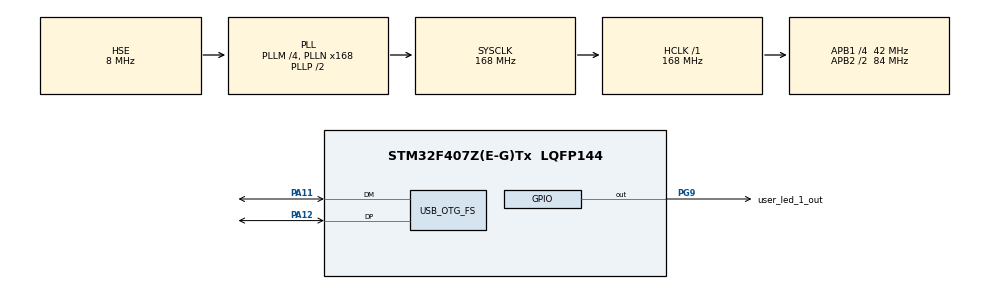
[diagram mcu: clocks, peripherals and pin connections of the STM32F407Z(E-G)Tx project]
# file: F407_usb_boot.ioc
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FATFS._MAX_SS=4096
FATFS._USE_LFN=1
Mcu.Family=STM32F4
Mcu.Name=STM32F407Z(E-G)Tx
Mcu.Package=LQFP144
NVIC.OTG_FS_IRQn=true\:0\:0\:false\:false\:true\:false\:true\:true
NVIC.PriorityGroup=NVIC_PRIORITYGROUP_4
PA11.Mode=Host_Only
PA11.Signal=USB_OTG_FS_DM
PA12.Mode=Host_Only
PA12.Signal=USB_OTG_FS_DP
PG9.GPIO_Label=user_led_1_out
PG9.Signal=GPIO_Output
PH0-OSC_IN.Mode=HSE-External-Oscillator
PH0-OSC_IN.Signal=RCC_OSC_IN
PH1-OSC_OUT.Mode=HSE-External-Oscillator
PH1-OSC_OUT.Signal=RCC_OSC_OUT
ProjectManager.HeapSize=0x200
ProjectManager.StackSize=0x400
ProjectManager.TargetToolchain=STM32CubeIDE
RCC.48MHZClocksFreq_Value=48000000
RCC.AHBFreq_Value=168000000
RCC.APB1CLKDivider=RCC_HCLK_DIV4
RCC.APB1Freq_Value=42000000
RCC.APB1TimFreq_Value=84000000
RCC.APB2CLKDivider=RCC_HCLK_DIV2
RCC.APB2Freq_Value=84000000
RCC.APB2TimFreq_Value=168000000
RCC.CortexFreq_Value=168000000
RCC.HCLKFreq_Value=168000000
RCC.HSE_VALUE=8000000
RCC.HSI_VALUE=16000000
RCC.LSE_VALUE=32768
RCC.PLLM=4
RCC.PLLN=168
RCC.PLLQ=7
RCC.SYSCLKFreq_VALUE=168000000
RCC.SYSCLKSource=RCC_SYSCLKSOURCE_PLLCLK
RCC.VCOOutputFreq_Value=336000000
USB_HOST.USBH_HandleTypeDef-MSC_FS=hUsbHostFS
USB_HOST.VirtualModeFS=Msc
USB_OTG_FS.VirtualMode=Host_Only
USB_OTG_FS.phy_itface=HCD_PHY_EMBEDDED
VP_FATFS_VS_USB.Mode=USB
VP_USB_HOST_VS_USB_HOST_MSC_FS.Mode=MSC_FS
board=custom

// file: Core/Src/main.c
/* USER CODE BEGIN Header */
/**
 ******************************************************************************
 * @file           : main.c
 * @brief          : Main program body
 ******************************************************************************
 * @attention
 *
 * Copyright (c) 2024 STMicroelectronics.
 * All rights reserved.
 *
 * This software is licensed under terms that can be found in the LICENSE file
 * in the root directory of this software component.
 * If no LICENSE file comes with this software, it is provided AS-IS.
 *
 ******************************************************************************
 */
/* USER CODE END Header */
#include "main.h"
#include "fatfs.h"
#include "usb_host.h"
#include "gpio.h"

/* USER CODE BEGIN PD */
#define application_address 	0x08040000
#define bufferSize 				512
#define file_name				"0:/F407_usb_app.bin"
#define usb_mount 				f_mount(&fatfs, USBHPath, 0)
#define usb_unmount 			f_mount(NULL, USBHPath, 0)
/* USER CODE END PD */

/* USER CODE BEGIN PV */
extern ApplicationTypeDef Appli_state;

uint32_t start = 0, end = 0;

FATFS fatfs;
FIL fil;
FRESULT fresult;
FILINFO info;

UINT bytesRead = 0;
uint8_t readBuffer[bufferSize];
/* USER CODE END PV */

void SystemClock_Config(void);
void MX_USB_HOST_Process(void);

/* USER CODE BEGIN PFP */
static void gotoApp(void);
/* USER CODE END PFP */

/* USER CODE BEGIN 0 */
void flashErase(void) {
	HAL_StatusTypeDef res;
	uint32_t sectorError;

	HAL_FLASH_Unlock();
	/* Check if the FLASH_FLAG_BSY */
	FLASH_WaitForLastOperation(HAL_MAX_DELAY);

	/* Clear all flags before write it to flash */
	__HAL_FLASH_CLEAR_FLAG(
			FLASH_FLAG_EOP | FLASH_FLAG_OPERR | FLASH_FLAG_WRPERR | FLASH_FLAG_PGAERR | FLASH_FLAG_PGPERR | FLASH_FLAG_PGSERR);

	/* Erase the flash */
	FLASH_EraseInitTypeDef flashErase;

	flashErase.TypeErase = FLASH_TYPEERASE_SECTORS;
	flashErase.Sector = FLASH_SECTOR_5;
	flashErase.NbSectors = 2;
	flashErase.VoltageRange = FLASH_VOLTAGE_RANGE_3;

	res = HAL_FLASHEx_Erase(&flashErase, &sectorError);
	if (res != HAL_OK) {
	}
}

void flashProgram(void) {
	uint32_t programBytesToRead = info.fsize;  // Get file size
	uint32_t currentAddress = application_address;

	while (programBytesToRead > 0) {
		// Read up to 512 bytes from the file
		if ((fresult = f_read(&fil, readBuffer, bufferSize, &bytesRead))
				!= FR_OK) {
		}

		// Write the data into flash memory, 4 bytes at a time
		for (uint32_t i = 0; i < bytesRead; i += 4) {
			HAL_FLASH_Program(FLASH_TYPEPROGRAM_WORD, currentAddress,
					*(uint32_t*) &readBuffer[i]);
			currentAddress += 4;
		}

		programBytesToRead -= bytesRead;
	}
	HAL_FLASH_Lock();
}
/* USER CODE END 0 */

int main(void) {

	/* MCU Configuration--------------------------------------------------------*/

	/* Reset of all peripherals, Initializes the Flash interface and the Systick. */
	HAL_Init();

	/* Configure the system clock */
	SystemClock_Config();

	/* Initialize all configured peripherals */
	MX_GPIO_Init();
	MX_FATFS_Init();
	MX_USB_HOST_Init();
	/* USER CODE BEGIN 2 */
	usb_mount;
	/* USER CODE END 2 */

	/* Infinite loop */
	while (1) {
		MX_USB_HOST_Process();

		/* USER CODE BEGIN 3 */
		end = HAL_GetTick() - start;
		if (end > 2000) {
			gotoApp();
		}
		if (Appli_state == APPLICATION_READY && end < 2000) {
			if ((fresult = f_open(&fil, file_name, FA_READ | FA_OPEN_ALWAYS))
					!= FR_OK) {
			} else {
				f_stat(file_name, &info);
				flashErase();
				flashProgram();

				fresult = f_close(&fil);
			}
			gotoApp();
		}
	}
	/* USER CODE END 3 */
}

void SystemClock_Config(void) {
	RCC_OscInitTypeDef RCC_OscInitStruct = { 0 };
	RCC_ClkInitTypeDef RCC_ClkInitStruct = { 0 };

	/** Configure the main internal regulator output voltage
	 */
	__HAL_RCC_PWR_CLK_ENABLE();
	__HAL_PWR_VOLTAGESCALING_CONFIG(PWR_REGULATOR_VOLTAGE_SCALE1);

	/** Initializes the RCC Oscillators according to the specified parameters
	 * in the RCC_OscInitTypeDef structure.
	 */
	RCC_OscInitStruct.OscillatorType = RCC_OSCILLATORTYPE_HSE;
	RCC_OscInitStruct.HSEState = RCC_HSE_ON;
	RCC_OscInitStruct.PLL.PLLState = RCC_PLL_ON;
	RCC_OscInitStruct.PLL.PLLSource = RCC_PLLSOURCE_HSE;
	RCC_OscInitStruct.PLL.PLLM = 4;
	RCC_OscInitStruct.PLL.PLLN = 168;
	RCC_OscInitStruct.PLL.PLLP = RCC_PLLP_DIV2;
	RCC_OscInitStruct.PLL.PLLQ = 7;
	if (HAL_RCC_OscConfig(&RCC_OscInitStruct) != HAL_OK) {
		Error_Handler();
	}

	/** Initializes the CPU, AHB and APB buses clocks
	 */
	RCC_ClkInitStruct.ClockType = RCC_CLOCKTYPE_HCLK | RCC_CLOCKTYPE_SYSCLK
			| RCC_CLOCKTYPE_PCLK1 | RCC_CLOCKTYPE_PCLK2;
	RCC_ClkInitStruct.SYSCLKSource = RCC_SYSCLKSOURCE_PLLCLK;
	RCC_ClkInitStruct.AHBCLKDivider = RCC_SYSCLK_DIV1;
	RCC_ClkInitStruct.APB1CLKDivider = RCC_HCLK_DIV4;
	RCC_ClkInitStruct.APB2CLKDivider = RCC_HCLK_DIV2;

	if (HAL_RCC_ClockConfig(&RCC_ClkInitStruct, FLASH_LATENCY_5) != HAL_OK) {
		Error_Handler();
	}
}

/* USER CODE BEGIN 4 */
static void gotoApp(void) {
	void (*appResetHandler)(
			void) = (void*)(*((volatile uint32_t *)(application_address + 4U)));

	HAL_GPIO_WritePin(user_led_1_out_GPIO_Port, user_led_1_out_Pin, GPIO_PIN_SET);

	HAL_RCC_DeInit();
	HAL_DeInit();
	SysTick->CTRL = 0;
	SysTick->LOAD = 0;
	SysTick->VAL = 0;

	__set_MSP(*(volatile uint32_t*) application_address);
	/*Jump to application*/
	appResetHandler(); // call the appResetHandler function
}
/* USER CODE END 4 */

void Error_Handler(void) {
	__disable_irq();
	while (1) {
	}
}
